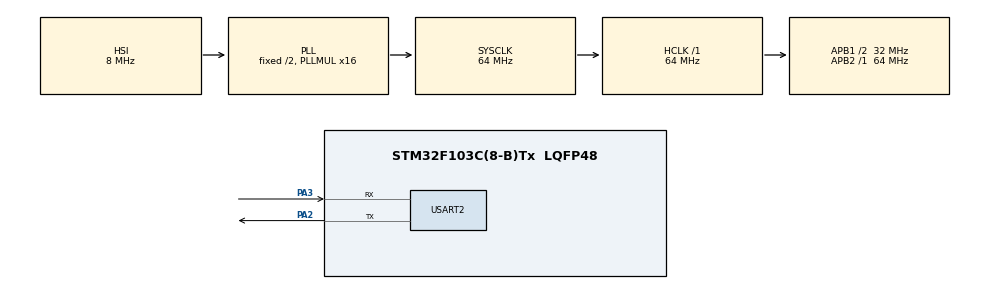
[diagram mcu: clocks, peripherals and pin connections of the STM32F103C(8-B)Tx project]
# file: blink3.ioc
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Mcu.Family=STM32F1
Mcu.Name=STM32F103C(8-B)Tx
Mcu.Package=LQFP48
NVIC.PriorityGroup=NVIC_PRIORITYGROUP_4
NVIC.USART2_IRQn=true\:0\:0\:false\:false\:true\:true\:true
PA13.Mode=Serial_Wire
PA13.Signal=SYS_JTMS-SWDIO
PA14.Mode=Serial_Wire
PA14.Signal=SYS_JTCK-SWCLK
PA2.Mode=Asynchronous
PA2.Signal=USART2_TX
PA3.Mode=Asynchronous
PA3.Signal=USART2_RX
ProjectManager.HeapSize=0x200
ProjectManager.StackSize=0x400
ProjectManager.TargetToolchain=MDK-ARM V5.27
RCC.AHBFreq_Value=64000000
RCC.APB1CLKDivider=RCC_HCLK_DIV2
RCC.APB1Freq_Value=32000000
RCC.APB1TimFreq_Value=64000000
RCC.APB2Freq_Value=64000000
RCC.APB2TimFreq_Value=64000000
RCC.HCLKFreq_Value=64000000
RCC.PLLMUL=RCC_PLL_MUL16
RCC.SYSCLKFreq_VALUE=64000000
RCC.SYSCLKSource=RCC_SYSCLKSOURCE_PLLCLK
RCC.USBFreq_Value=64000000
USART2.VirtualMode=VM_ASYNC
board=custom

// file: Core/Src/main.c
/* USER CODE BEGIN Header */
/**
  ******************************************************************************
  * @file           : main.c
  * @brief          : Main program body
  ******************************************************************************
  * @attention
  *
  * <h2><center>&copy; Copyright (c) 2021 STMicroelectronics.
  * All rights reserved.</center></h2>
  *
  * This software component is licensed by ST under BSD 3-Clause license,
  * the "License"; You may not use this file except in compliance with the
  * License. You may obtain a copy of the License at:
  *                        opensource.org/licenses/BSD-3-Clause
  *
  ******************************************************************************
  */
/* USER CODE END Header */
#include "main.h"
#include "usart.h"
#include "gpio.h"
#include "stdio.h"

/* USER CODE BEGIN PD */
#define LENGTH      10
/* USER CODE END PD */

/* USER CODE BEGIN PV */
uint8_t RxBuffer[LENGTH];
uint8_t RxFlag = 0;
/* USER CODE END PV */

void SystemClock_Config(void);

int main(void)
{

  /* MCU Configuration--------------------------------------------------------*/

  /* Reset of all peripherals, Initializes the Flash interface and the Systick. */
  HAL_Init();

  /* Configure the system clock */
  SystemClock_Config();

  /* Initialize all configured peripherals */
  MX_GPIO_Init();
  MX_USART2_UART_Init();
  /* USER CODE BEGIN 2 */
printf("**********UART communication***********");
printf("ten");
HAL_UART_Receive_IT(&huart2,(uint8_t*)RxBuffer,LENGTH);
  /* USER CODE END 2 */

  /* Infinite loop */
  while (1)
  {

    /* USER CODE BEGIN 3 */
		if(RxFlag==1)
		{
			RxFlag = 0;
			printf("success!");
			HAL_UART_Transmit_IT(&huart2,(uint8_t*)RxBuffer,LENGTH);
		}
  }
  /* USER CODE END 3 */
}

void SystemClock_Config(void)
{
  RCC_OscInitTypeDef RCC_OscInitStruct = {0};
  RCC_ClkInitTypeDef RCC_ClkInitStruct = {0};

  /** Initializes the RCC Oscillators according to the specified parameters
  * in the RCC_OscInitTypeDef structure.
  */
  RCC_OscInitStruct.OscillatorType = RCC_OSCILLATORTYPE_HSI;
  RCC_OscInitStruct.HSIState = RCC_HSI_ON;
  RCC_OscInitStruct.HSICalibrationValue = RCC_HSICALIBRATION_DEFAULT;
  RCC_OscInitStruct.PLL.PLLState = RCC_PLL_ON;
  RCC_OscInitStruct.PLL.PLLSource = RCC_PLLSOURCE_HSI_DIV2;
  RCC_OscInitStruct.PLL.PLLMUL = RCC_PLL_MUL16;
  if (HAL_RCC_OscConfig(&RCC_OscInitStruct) != HAL_OK)
  {
    Error_Handler();
  }
  /** Initializes the CPU, AHB and APB buses clocks
  */
  RCC_ClkInitStruct.ClockType = RCC_CLOCKTYPE_HCLK|RCC_CLOCKTYPE_SYSCLK
                              |RCC_CLOCKTYPE_PCLK1|RCC_CLOCKTYPE_PCLK2;
  RCC_ClkInitStruct.SYSCLKSource = RCC_SYSCLKSOURCE_PLLCLK;
  RCC_ClkInitStruct.AHBCLKDivider = RCC_SYSCLK_DIV1;
  RCC_ClkInitStruct.APB1CLKDivider = RCC_HCLK_DIV2;
  RCC_ClkInitStruct.APB2CLKDivider = RCC_HCLK_DIV1;

  if (HAL_RCC_ClockConfig(&RCC_ClkInitStruct, FLASH_LATENCY_2) != HAL_OK)
  {
    Error_Handler();
  }
}

/* USER CODE BEGIN 4 */
void HAL_UART_RxCpltCallback(UART_HandleTypeDef *haurt)
{
	if (haurt ->Instance ==USART2)
	{
		RxFlag =1;
	  HAL_UART_Receive_IT(&huart2,(uint8_t*)RxBuffer,LENGTH);
	}
}
/* USER CODE END 4 */

void Error_Handler(void)
{
  __disable_irq();
  while (1)
  {
  }
}

/************************ (C) COPYRIGHT STMicroelectronics *****END OF FILE****/
